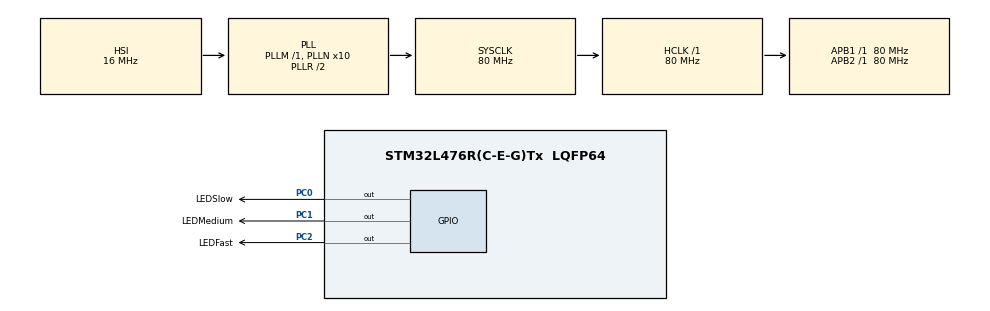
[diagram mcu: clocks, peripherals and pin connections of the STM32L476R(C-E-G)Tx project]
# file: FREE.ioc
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FREERTOS.Tasks01=defaultTask,24,128,StartDefaultTask,Default,NULL,Dynamic,NULL,NULL
Mcu.Family=STM32L4
Mcu.Name=STM32L476R(C-E-G)Tx
Mcu.Package=LQFP64
NVIC.PriorityGroup=NVIC_PRIORITYGROUP_4
PC0.GPIO_Label=LEDSlow
PC0.Signal=GPIO_Output
PC1.GPIO_Label=LEDMedium
PC1.Signal=GPIO_Output
PC2.GPIO_Label=LEDFast
PC2.Signal=GPIO_Output
PH0-OSC_IN\ (PH0).Mode=HSE-External-Oscillator
PH0-OSC_IN\ (PH0).Signal=RCC_OSC_IN
PH1-OSC_OUT\ (PH1).Mode=HSE-External-Oscillator
PH1-OSC_OUT\ (PH1).Signal=RCC_OSC_OUT
ProjectManager.HeapSize=0x200
ProjectManager.StackSize=0x400
ProjectManager.TargetToolchain=STM32CubeIDE
RCC.ADCFreq_Value=64000000
RCC.AHBFreq_Value=80000000
RCC.APB1Freq_Value=80000000
RCC.APB1TimFreq_Value=80000000
RCC.APB2Freq_Value=80000000
RCC.APB2TimFreq_Value=80000000
RCC.CortexFreq_Value=80000000
RCC.HCLKFreq_Value=80000000
RCC.HSE_VALUE=8000000
RCC.HSI_VALUE=16000000
RCC.LSE_VALUE=32768
RCC.MSI_VALUE=4000000
RCC.PLLN=10
RCC.PLLSourceVirtual=RCC_PLLSOURCE_HSI
RCC.SYSCLKFreq_VALUE=80000000
RCC.SYSCLKSource=RCC_SYSCLKSOURCE_PLLCLK
RCC.USBFreq_Value=64000000
RCC.VCOOutputFreq_Value=160000000
VP_FREERTOS_VS_CMSIS_V2.Mode=CMSIS_V2
board=custom

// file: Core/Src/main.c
/* USER CODE BEGIN Header */
/**
  ******************************************************************************
  * @file           : main.c
  * @brief          : Main program body
  ******************************************************************************
  * @attention
  *
  * Copyright (c) 2024 STMicroelectronics.
  * All rights reserved.
  *
  * This software is licensed under terms that can be found in the LICENSE file
  * in the root directory of this software component.
  * If no LICENSE file comes with this software, it is provided AS-IS.
  *
  ******************************************************************************
  */
/* USER CODE END Header */
#include "main.h"
#include "cmsis_os.h"

/* USER CODE BEGIN Includes */
osThreadId_t LEDSTaskhandle;
osThreadId_t LEDMTaskHandle;
osThreadId_t LEDFTaskHandle;

void StartLEDSTask(void * argument)
{

	for(;;)
	{

		HAL_GPIO_TogglePin(LEDSlow_GPIO_Port, LEDSlow_Pin);
		osDelay(1000);

	}

}

void StartLEDMTask(void * argument)
{

	for(;;)
	{

		HAL_GPIO_TogglePin(LEDMedium_GPIO_Port, LEDMedium_Pin);
		osDelay(500);

	}

}

void StartLEDFTask(void * argument)
{

	for(;;)
	{

		HAL_GPIO_TogglePin(LEDFast_GPIO_Port, LEDFast_Pin);
		osDelay(250);

	}

}
/* USER CODE END Includes */

/* Definitions for defaultTask */
osThreadId_t defaultTaskHandle;
const osThreadAttr_t defaultTask_attributes = {
  .name = "defaultTask",
  .stack_size = 128 * 4,
  .priority = (osPriority_t) osPriorityNormal,
};

void SystemClock_Config(void);
static void MX_GPIO_Init(void);
void StartDefaultTask(void *argument);

int main(void)
{

  /* MCU Configuration--------------------------------------------------------*/

  /* Reset of all peripherals, Initializes the Flash interface and the Systick. */
  HAL_Init();

  /* Configure the system clock */
  SystemClock_Config();

  /* Initialize all configured peripherals */
  MX_GPIO_Init();
  /* USER CODE BEGIN 2 */

  const osThreadAttr_t LEDSTask_attributes =
  {
		  .name="LEDStask",
		  .priority=((osPriority)osPriorityNormal),
		  .stack_size=128*4
  };

  const osThreadAttr_t LEDMTask_attributes =
    {
  		  .name="LEDMtask",
  		  .priority=((osPriority)osPriorityNormal),
  		  .stack_size=128*4
    };

  const osThreadAttr_t LEDFTask_attributes =
    {
  		  .name="LEDFtask",
  		  .priority=((osPriority)osPriorityNormal),
  		  .stack_size=128*4
    };

  LEDSTaskhandle = osThreadNew(StartLEDSTask, NULL, &LEDSTask_attributes);
  LEDMTaskHandle = osThreadNew(StartLEDMTask, NULL, &LEDMTask_attributes);
  LEDFTaskHandle = osThreadNew(StartLEDFTask, NULL, &LEDFTask_attributes);

  /* USER CODE END 2 */

  /* Init scheduler */
  osKernelInitialize();

  /* Create the thread(s) */
  /* creation of defaultTask */
  defaultTaskHandle = osThreadNew(StartDefaultTask, NULL, &defaultTask_attributes);

  /* Start scheduler */
  osKernelStart();

  /* We should never get here as control is now taken by the scheduler */
  /* Infinite loop */
  while (1)
  {

  }
}

void SystemClock_Config(void)
{
  RCC_OscInitTypeDef RCC_OscInitStruct = {0};
  RCC_ClkInitTypeDef RCC_ClkInitStruct = {0};

  /** Configure the main internal regulator output voltage
  */
  if (HAL_PWREx_ControlVoltageScaling(PWR_REGULATOR_VOLTAGE_SCALE1) != HAL_OK)
  {
    Error_Handler();
  }

  /** Initializes the RCC Oscillators according to the specified parameters
  * in the RCC_OscInitTypeDef structure.
  */
  RCC_OscInitStruct.OscillatorType = RCC_OSCILLATORTYPE_HSI;
  RCC_OscInitStruct.HSIState = RCC_HSI_ON;
  RCC_OscInitStruct.HSICalibrationValue = RCC_HSICALIBRATION_DEFAULT;
  RCC_OscInitStruct.PLL.PLLState = RCC_PLL_ON;
  RCC_OscInitStruct.PLL.PLLSource = RCC_PLLSOURCE_HSI;
  RCC_OscInitStruct.PLL.PLLM = 1;
  RCC_OscInitStruct.PLL.PLLN = 10;
  RCC_OscInitStruct.PLL.PLLP = RCC_PLLP_DIV7;
  RCC_OscInitStruct.PLL.PLLQ = RCC_PLLQ_DIV2;
  RCC_OscInitStruct.PLL.PLLR = RCC_PLLR_DIV2;
  if (HAL_RCC_OscConfig(&RCC_OscInitStruct) != HAL_OK)
  {
    Error_Handler();
  }

  /** Initializes the CPU, AHB and APB buses clocks
  */
  RCC_ClkInitStruct.ClockType = RCC_CLOCKTYPE_HCLK|RCC_CLOCKTYPE_SYSCLK
                              |RCC_CLOCKTYPE_PCLK1|RCC_CLOCKTYPE_PCLK2;
  RCC_ClkInitStruct.SYSCLKSource = RCC_SYSCLKSOURCE_PLLCLK;
  RCC_ClkInitStruct.AHBCLKDivider = RCC_SYSCLK_DIV1;
  RCC_ClkInitStruct.APB1CLKDivider = RCC_HCLK_DIV1;
  RCC_ClkInitStruct.APB2CLKDivider = RCC_HCLK_DIV1;

  if (HAL_RCC_ClockConfig(&RCC_ClkInitStruct, FLASH_LATENCY_4) != HAL_OK)
  {
    Error_Handler();
  }
}

static void MX_GPIO_Init(void)
{
  GPIO_InitTypeDef GPIO_InitStruct = {0};

  /* GPIO Ports Clock Enable */
  __HAL_RCC_GPIOH_CLK_ENABLE();
  __HAL_RCC_GPIOC_CLK_ENABLE();

  /*Configure GPIO pin Output Level */
  HAL_GPIO_WritePin(GPIOC, LEDSlow_Pin|LEDMedium_Pin|LEDFast_Pin, GPIO_PIN_RESET);

  /*Configure GPIO pins : LEDSlow_Pin LEDMedium_Pin LEDFast_Pin */
  GPIO_InitStruct.Pin = LEDSlow_Pin|LEDMedium_Pin|LEDFast_Pin;
  GPIO_InitStruct.Mode = GPIO_MODE_OUTPUT_PP;
  GPIO_InitStruct.Pull = GPIO_NOPULL;
  GPIO_InitStruct.Speed = GPIO_SPEED_FREQ_LOW;
  HAL_GPIO_Init(GPIOC, &GPIO_InitStruct);

}

void StartDefaultTask(void *argument)
{
  for(;;)
  {
    osDelay(1);
  }
}

void Error_Handler(void)
{
  __disable_irq();
  while (1)
  {
  }
}
